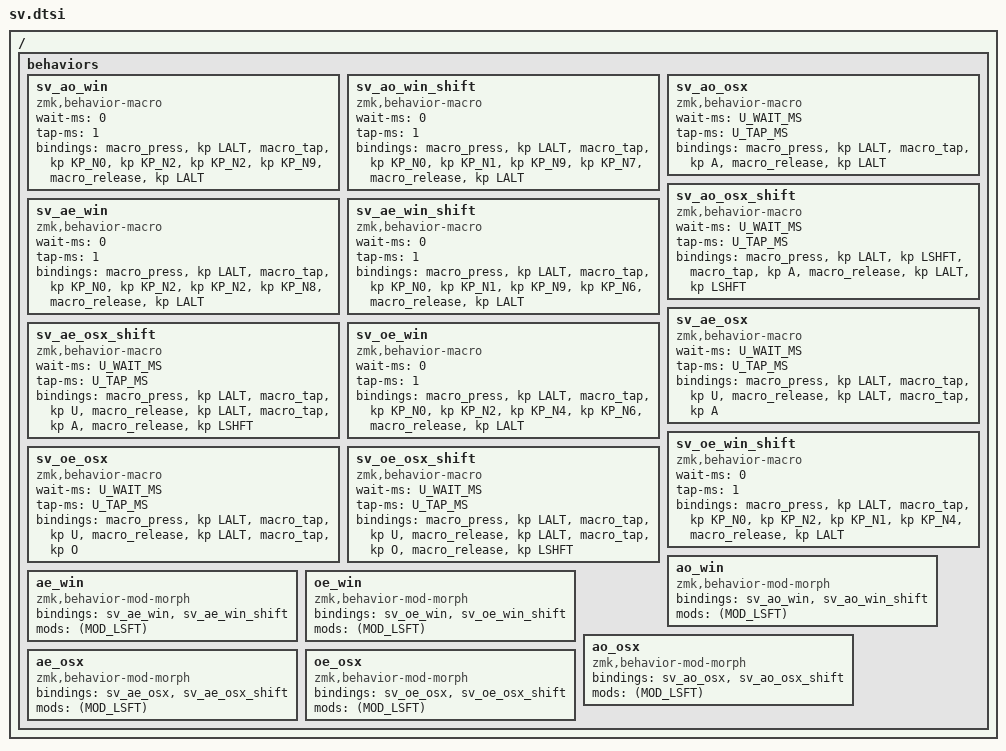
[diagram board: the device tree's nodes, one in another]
#include "zmk-helpers/helper.h"

#define U_TAP_MS 40
#define U_WAIT_MS 40

ZMK_MACRO(sv_ao_win,
    wait-ms = <0>;
    tap-ms = <1>;
    bindings = <&macro_press   &kp LALT>
             , <&macro_tap     &kp KP_N0 &kp KP_N2 &kp KP_N2 &kp KP_N9>
             , <&macro_release &kp LALT>;
)
ZMK_MACRO(sv_ao_win_shift,
    wait-ms = <0>;
    tap-ms = <1>;
    bindings = <&macro_press   &kp LALT>
             , <&macro_tap     &kp KP_N0 &kp KP_N1 &kp KP_N9 &kp KP_N7>
             , <&macro_release &kp LALT>;
)

ZMK_MACRO(sv_ao_osx,
    wait-ms = <U_WAIT_MS>;
    tap-ms = <U_TAP_MS>;
    bindings = <&macro_press   &kp LALT>
             , <&macro_tap     &kp A>
             , <&macro_release &kp LALT>;
)
ZMK_MACRO(sv_ao_osx_shift,
    wait-ms = <U_WAIT_MS>;
    tap-ms = <U_TAP_MS>;
    bindings = <&macro_press   &kp LALT &kp LSHFT>
             , <&macro_tap     &kp A>
             , <&macro_release &kp LALT &kp LSHFT>;
)


ZMK_MACRO(sv_ae_win,
    wait-ms = <0>;
    tap-ms = <1>;
    bindings = <&macro_press   &kp LALT>
             , <&macro_tap     &kp KP_N0 &kp KP_N2 &kp KP_N2 &kp KP_N8>
             , <&macro_release &kp LALT>;
)
ZMK_MACRO(sv_ae_win_shift,
    wait-ms = <0>;
    tap-ms = <1>;
    bindings = <&macro_press   &kp LALT>
             , <&macro_tap     &kp KP_N0 &kp KP_N1 &kp KP_N9 &kp KP_N6>
             , <&macro_release &kp LALT>;
)

ZMK_MACRO(sv_ae_osx,
    wait-ms = <U_WAIT_MS>;
    tap-ms = <U_TAP_MS>;
    bindings = <&macro_press   &kp LALT>
             , <&macro_tap     &kp U>
             , <&macro_release &kp LALT>
             , <&macro_tap     &kp A>;
)
ZMK_MACRO(sv_ae_osx_shift,
    wait-ms = <U_WAIT_MS>;
    tap-ms = <U_TAP_MS>;

    bindings = <&macro_press   &kp LALT>
             , <&macro_tap     &kp U>
             , <&macro_release &kp LALT>
             , <&macro_tap     &kp A>
             , <&macro_release &kp LSHFT>;
)

ZMK_MACRO(sv_oe_win,
    wait-ms = <0>;
    tap-ms = <1>;
    bindings = <&macro_press   &kp LALT>
             , <&macro_tap     &kp KP_N0 &kp KP_N2 &kp KP_N4 &kp KP_N6>
             , <&macro_release &kp LALT>;
)
ZMK_MACRO(sv_oe_win_shift,
    wait-ms = <0>;
    tap-ms = <1>;
    bindings = <&macro_press   &kp LALT>
             , <&macro_tap     &kp KP_N0 &kp KP_N2 &kp KP_N1 &kp KP_N4>
             , <&macro_release &kp LALT>;
)

ZMK_MACRO(sv_oe_osx,
    wait-ms = <U_WAIT_MS>;
    tap-ms = <U_TAP_MS>;
    bindings = <&macro_press   &kp LALT>
             , <&macro_tap     &kp U>
             , <&macro_release &kp LALT>
             , <&macro_tap     &kp O>;
)

ZMK_MACRO(sv_oe_osx_shift,
    wait-ms = <U_WAIT_MS>;
    tap-ms = <U_TAP_MS>;

    bindings = <&macro_press   &kp LALT>
             , <&macro_tap     &kp U>
             , <&macro_release &kp LALT>
             , <&macro_tap     &kp O>
             , <&macro_release &kp LSHFT>;
)

ZMK_MOD_MORPH(ao_win,
    bindings = <&sv_ao_win>, <&sv_ao_win_shift>;
    mods = <(MOD_LSFT)>;
)
ZMK_MOD_MORPH(ae_win,
    bindings = <&sv_ae_win>, <&sv_ae_win_shift>;
    mods = <(MOD_LSFT)>;
)
ZMK_MOD_MORPH(oe_win,
    bindings = <&sv_oe_win>, <&sv_oe_win_shift>;
    mods = <(MOD_LSFT)>;
)

ZMK_MOD_MORPH(ao_osx,
    bindings = <&sv_ao_osx>, <&sv_ao_osx_shift>;
    mods = <(MOD_LSFT)>;
)
ZMK_MOD_MORPH(ae_osx,
    bindings = <&sv_ae_osx>, <&sv_ae_osx_shift>;
    mods = <(MOD_LSFT)>;
)
ZMK_MOD_MORPH(oe_osx,
    bindings = <&sv_oe_osx>, <&sv_oe_osx_shift>;
    mods = <(MOD_LSFT)>;
)
